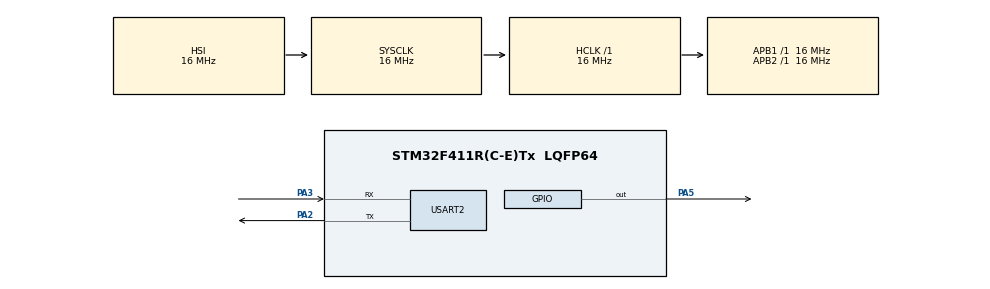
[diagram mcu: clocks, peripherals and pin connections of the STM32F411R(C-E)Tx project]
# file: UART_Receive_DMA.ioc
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Dma.Request0=USART2_RX
Dma.USART2_RX.0.Direction=DMA_PERIPH_TO_MEMORY
Dma.USART2_RX.0.FIFOMode=DMA_FIFOMODE_DISABLE
Dma.USART2_RX.0.Instance=DMA1_Stream5
Dma.USART2_RX.0.MemDataAlignment=DMA_MDATAALIGN_BYTE
Dma.USART2_RX.0.MemInc=DMA_MINC_ENABLE
Dma.USART2_RX.0.Mode=DMA_NORMAL
Dma.USART2_RX.0.PeriphDataAlignment=DMA_PDATAALIGN_BYTE
Dma.USART2_RX.0.PeriphInc=DMA_PINC_DISABLE
Dma.USART2_RX.0.Priority=DMA_PRIORITY_LOW
Mcu.Family=STM32F4
Mcu.Name=STM32F411R(C-E)Tx
Mcu.Package=LQFP64
NVIC.DMA1_Stream5_IRQn=true\:0\:0\:false\:false\:true\:false\:true\:true
NVIC.PriorityGroup=NVIC_PRIORITYGROUP_4
NVIC.USART2_IRQn=true\:0\:0\:false\:false\:true\:true\:true\:true
PA2.Mode=Asynchronous
PA2.Signal=USART2_TX
PA3.Mode=Asynchronous
PA3.Signal=USART2_RX
PA5.Signal=GPIO_Output
ProjectManager.HeapSize=0x200
ProjectManager.StackSize=0x400
ProjectManager.TargetToolchain=STM32CubeIDE
RCC.AHBFreq_Value=16000000
RCC.APB1Freq_Value=16000000
RCC.APB2Freq_Value=16000000
RCC.CortexFreq_Value=16000000
RCC.HSE_VALUE=25000000
RCC.HSI_VALUE=16000000
RCC.LSE_VALUE=32768
RCC.SYSCLKFreq_VALUE=16000000
RCC.VCOOutputFreq_Value=192000000
USART2.VirtualMode=VM_ASYNC
board=custom

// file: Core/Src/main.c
/* USER CODE BEGIN Header */
/**
  ******************************************************************************
  * @file           : main.c
  * @brief          : Main program body
  ******************************************************************************
  * @attention
  *
  * Copyright (c) 2025 STMicroelectronics.
  * All rights reserved.
  *
  * This software is licensed under terms that can be found in the LICENSE file
  * in the root directory of this software component.
  * If no LICENSE file comes with this software, it is provided AS-IS.
  *
  ******************************************************************************
  */
/* USER CODE END Header */
#include "main.h"

/* USER CODE BEGIN Includes */
#include <stdbool.h>
/* USER CODE END Includes */

UART_HandleTypeDef huart2;
DMA_HandleTypeDef hdma_usart2_rx;

void SystemClock_Config(void);
static void MX_GPIO_Init(void);
static void MX_DMA_Init(void);
static void MX_USART2_UART_Init(void);

/* USER CODE BEGIN 0 */
uint8_t RxData[20];
uint32_t count_half = 0;
uint32_t count_full = 0;

uint8_t RxBigData[4096]; //The buffer to store data
bool isSizeRxed = 0; //A flag to indicate if the size of the data has been received
uint32_t size = 0; //Size of the data

//RECEIVING DATA IN CHUNKS
/*
void HAL_UART_RxHalfCpltCallback(UART_HandleTypeDef *huart)
{
	count_half++;
}
//----------------------------------------------------------
void HAL_UART_RxCpltCallback(UART_HandleTypeDef *huart)
{
	count_full++;
	HAL_UART_Receive_DMA(&huart2, RxData, 10); //In the normal mode DMA gets disabled after each session of receiving data.
	//So we need to call the function here again.
}
*/

//RECEIVING ALL DATA AT ONCE
void HAL_UART_RxCpltCallback(UART_HandleTypeDef *haurt)
{
	if (!isSizeRxed)
	{
		//Extract the value of the size from the received data. 48 is an offset of the value
		size = (RxBigData[0] - 48)*1000 + (RxBigData[1] - 48)*100 + (RxBigData[2] - 48)*10 + RxBigData[3] - 48;
		isSizeRxed = 1;
		HAL_UART_Receive_DMA(&huart2, RxBigData, size);
	}
	else if (isSizeRxed)
	{
		HAL_UART_Receive_DMA(&huart2, RxBigData, 4); // Receiving the 4 bytes of the size
		isSizeRxed = 0;
	}
}

/* USER CODE END 0 */

int main(void)
{

  /* USER CODE BEGIN 1 */
	//DMA is used to receive large data so that the CPU can handle the rest of the tasks

  /* USER CODE END 1 */

  /* MCU Configuration--------------------------------------------------------*/

  /* Reset of all peripherals, Initializes the Flash interface and the Systick. */
  HAL_Init();

  /* Configure the system clock */
  SystemClock_Config();

  /* Initialize all configured peripherals */
  MX_GPIO_Init();
  MX_DMA_Init();
  MX_USART2_UART_Init();
  /* USER CODE BEGIN 2 */
  //FUNCTION FOR DOUBLE RECEIVING
  HAL_UART_Receive_DMA(&huart2, RxData, 10); //DMA Receive comes with 2 interrupts:
  //1st is called when half of data has been received, and 2nd is called when the total data has been received.

  //FUNCTION FOR SINGLE RECEIVING
  HAL_UART_Receive_DMA(&huart2, RxBigData, 4); //We need to receive the four bytes of the size first

  /* USER CODE END 2 */

  /* Infinite loop */
  /* USER CODE BEGIN WHILE */
  while (1)
  {
    HAL_GPIO_TogglePin(GPIOA, GPIO_PIN_5);
    HAL_Delay(1000);

	  /* USER CODE END WHILE */

  }
}

void SystemClock_Config(void)
{
  RCC_OscInitTypeDef RCC_OscInitStruct = {0};
  RCC_ClkInitTypeDef RCC_ClkInitStruct = {0};

  /** Configure the main internal regulator output voltage
  */
  __HAL_RCC_PWR_CLK_ENABLE();
  __HAL_PWR_VOLTAGESCALING_CONFIG(PWR_REGULATOR_VOLTAGE_SCALE1);

  /** Initializes the RCC Oscillators according to the specified parameters
  * in the RCC_OscInitTypeDef structure.
  */
  RCC_OscInitStruct.OscillatorType = RCC_OSCILLATORTYPE_HSI;
  RCC_OscInitStruct.HSIState = RCC_HSI_ON;
  RCC_OscInitStruct.HSICalibrationValue = RCC_HSICALIBRATION_DEFAULT;
  RCC_OscInitStruct.PLL.PLLState = RCC_PLL_NONE;
  if (HAL_RCC_OscConfig(&RCC_OscInitStruct) != HAL_OK)
  {
    Error_Handler();
  }

  /** Initializes the CPU, AHB and APB buses clocks
  */
  RCC_ClkInitStruct.ClockType = RCC_CLOCKTYPE_HCLK|RCC_CLOCKTYPE_SYSCLK
                              |RCC_CLOCKTYPE_PCLK1|RCC_CLOCKTYPE_PCLK2;
  RCC_ClkInitStruct.SYSCLKSource = RCC_SYSCLKSOURCE_HSI;
  RCC_ClkInitStruct.AHBCLKDivider = RCC_SYSCLK_DIV1;
  RCC_ClkInitStruct.APB1CLKDivider = RCC_HCLK_DIV1;
  RCC_ClkInitStruct.APB2CLKDivider = RCC_HCLK_DIV1;

  if (HAL_RCC_ClockConfig(&RCC_ClkInitStruct, FLASH_LATENCY_0) != HAL_OK)
  {
    Error_Handler();
  }
}

static void MX_USART2_UART_Init(void)
{

  huart2.Instance = USART2;
  huart2.Init.BaudRate = 115200;
  huart2.Init.WordLength = UART_WORDLENGTH_8B;
  huart2.Init.StopBits = UART_STOPBITS_1;
  huart2.Init.Parity = UART_PARITY_NONE;
  huart2.Init.Mode = UART_MODE_TX_RX;
  huart2.Init.HwFlowCtl = UART_HWCONTROL_NONE;
  huart2.Init.OverSampling = UART_OVERSAMPLING_16;
  if (HAL_UART_Init(&huart2) != HAL_OK)
  {
    Error_Handler();
  }

}

static void MX_DMA_Init(void)
{

  /* DMA controller clock enable */
  __HAL_RCC_DMA1_CLK_ENABLE();

  /* DMA interrupt init */
  /* DMA1_Stream5_IRQn interrupt configuration */
  HAL_NVIC_SetPriority(DMA1_Stream5_IRQn, 0, 0);
  HAL_NVIC_EnableIRQ(DMA1_Stream5_IRQn);

}

static void MX_GPIO_Init(void)
{
  GPIO_InitTypeDef GPIO_InitStruct = {0};

  /* GPIO Ports Clock Enable */
  __HAL_RCC_GPIOA_CLK_ENABLE();

  /*Configure GPIO pin Output Level */
  HAL_GPIO_WritePin(GPIOA, GPIO_PIN_5, GPIO_PIN_RESET);

  /*Configure GPIO pin : PA5 */
  GPIO_InitStruct.Pin = GPIO_PIN_5;
  GPIO_InitStruct.Mode = GPIO_MODE_OUTPUT_PP;
  GPIO_InitStruct.Pull = GPIO_NOPULL;
  GPIO_InitStruct.Speed = GPIO_SPEED_FREQ_LOW;
  HAL_GPIO_Init(GPIOA, &GPIO_InitStruct);

}

void Error_Handler(void)
{
  __disable_irq();
  while (1)
  {
  }
}
